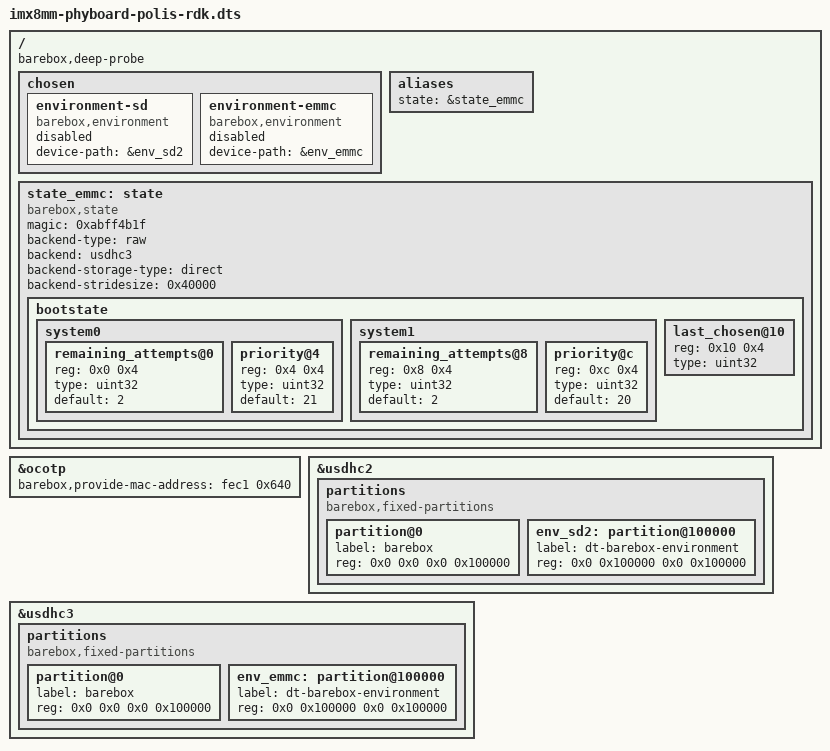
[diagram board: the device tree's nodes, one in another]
// SPDX-License-Identifier: (GPL-2.0 OR MIT)

/dts-v1/;

#include <arm64/freescale/imx8mm-phyboard-polis-rdk.dts>

/ {
	barebox,deep-probe;

	chosen {
		environment-sd {
			compatible = "barebox,environment";
			device-path = &env_sd2;
			status = "disabled";
		};
		environment-emmc {
			compatible = "barebox,environment";
			device-path = &env_emmc;
			status = "disabled";
		};
	};

	aliases {
		state = &state_emmc;
	};

	state_emmc: state {
		compatible = "barebox,state";
		magic = <0xabff4b1f>;
		backend-type = "raw";
		backend = <&usdhc3>;
		backend-storage-type="direct";
		/*
		 * barebox-state partition size: 1 MiB
		 * nr. of redundant copies:      4
		 * ==> max. stride size: 1 MiB / 4 = 256 KiB = 262144 Byte
		 *
		 * stride size:     262144 Byte
		 * raw-header:     -    16 Byte
		 * direct-storage: -     8 Byte
		 *                 ------------
		 * max state size:  262120 Byte
		 *                  ===========
		 */
		backend-stridesize = <0x40000>;
		#address-cells = <1>;
		#size-cells = <1>;

		bootstate {
			#address-cells = <1>;
			#size-cells = <1>;

			system0 {
				#address-cells = <1>;
				#size-cells = <1>;

				remaining_attempts@0 {
					reg = <0x0 0x4>;
					type = "uint32";
					default = <2>;
				};

				priority@4 {
					reg = <0x4 0x4>;
					type= "uint32";
					default = <21>;
				};
			};

			system1 {
				#address-cells = <1>;
				#size-cells = <1>;

				remaining_attempts@8 {
					reg = <0x8 0x4>;
					type = "uint32";
					default = <2>;
				};

				priority@c {
					reg = <0xc 0x4>;
					type= "uint32";
					default = <20>;
				};
			};

			last_chosen@10 {
				reg = <0x10 0x4>;
				type = "uint32";
			};
		};
	};
};

&ocotp {
	barebox,provide-mac-address = <&fec1 0x640>;
};

&usdhc2 {
	partitions {
		compatible = "barebox,fixed-partitions";
		#address-cells = <2>;
		#size-cells = <2>;

		partition@0 {
			label = "barebox";
			reg = <0x0 0x0 0x0 0x100000>;
		};

		env_sd2: partition@100000 {
			label = "dt-barebox-environment";
			reg = <0x0 0x100000 0x0 0x100000>;
		};
	};
};

&usdhc3 {
	partitions {
		compatible = "barebox,fixed-partitions";
		#address-cells = <2>;
		#size-cells = <2>;

		partition@0 {
			label = "barebox";
			reg = <0x0 0x0 0x0 0x100000>;
		};

		env_emmc: partition@100000 {
			label = "dt-barebox-environment";
			reg = <0x0 0x100000 0x0 0x100000>;
		};
	};
};
